# ATSAMA5D31 device description
Architecture: CORTEX-A5; Family: SAMA5
Registers are 32-bit, read-write, no defined reset value unless marked. A register's access mark holds for its fields unless they carry their own. Offsets are from the block's base; [hi:lo] are bit positions; {n}, {i} and the like mark numbered series; 'fields as' and 'values as' point back to an identical list.

## SCKC — Slow Clock Controller
Instances: SCKC 0xFFFFFE50
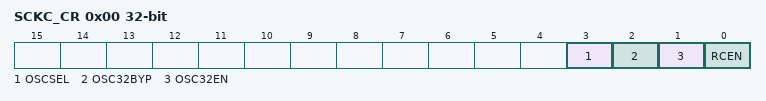
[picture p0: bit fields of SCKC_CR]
0x00 SCKC_CR — Slow Clock Configuration Register
  [3] OSCSEL — Slow Clock Selector
    0=RC (Slow clock is internal 32 kHz RC oscillator.); 1=XTAL (Slow clock is 32,768 Hz oscillator.)
  [2] OSC32BYP — 32,768Hz Oscillator Bypass
  [1] OSC32EN — 32,768 Hz Oscillator
  [0] RCEN — Internal 32 kHz RC Oscillator

## SFR — Special Function Registers
Instances: SFR 0xF0038000
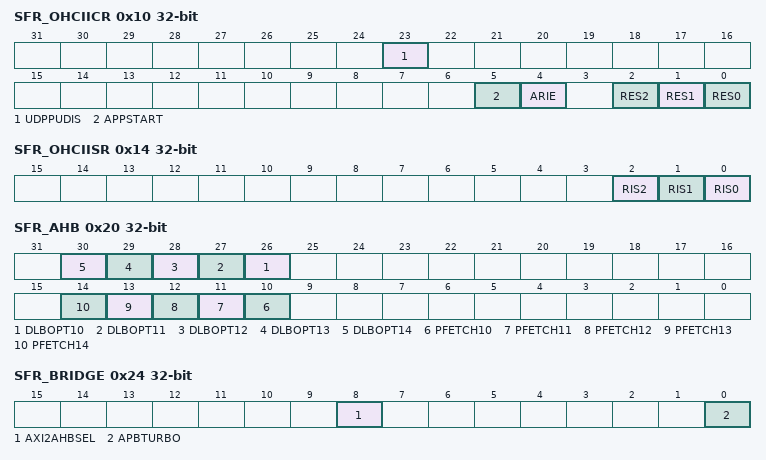
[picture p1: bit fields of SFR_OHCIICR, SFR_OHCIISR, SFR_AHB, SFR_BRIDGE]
0x10 SFR_OHCIICR — OHCI Interrupt Configuration Register
  [23] UDPPUDIS — OHCI USB DEVICE PULL-UP DISABLE
  [5] APPSTART — Reserved
  [4] ARIE — OHCI Asynchronous Resume Interrupt Enable
  [2] RES2 — USB PORTx RESET
  [1] RES1 — USB PORTx RESET
  [0] RES0 — USB PORTx RESET
0x14 SFR_OHCIISR ro — OHCI Interrupt Status Register
  [2] RIS2 — OHCI Resume Interrupt Status Port 2
  [1] RIS1 — OHCI Resume Interrupt Status Port 1
  [0] RIS0 — OHCI Resume Interrupt Status Port 0
0x20 SFR_AHB — AHB Configuration Register
  [n+16] DLBOPT{n} (n=10..14) — AHB MASTERx {n} Converter Define Length Burst Optimization
  [n] PFETCH{n} (n=10..14) — AHB MASTERx {n} Converter Prefetch
    0=INCR4 (INCR undefined burst converted to burst of 4 beats.); 1=INCR8 (INCR undefined burst converted to burst of 8 beats.)
0x24 SFR_BRIDGE — Bridge Configuration Register
  [8] AXI2AHBSEL — AXI to AHB bridge for DDR controller selection
    0=SINGLE (use single port bridge.); 1=DUAL (use dual port bridge.)
  [0] APBTURBO — AHB to APB Bridge mode
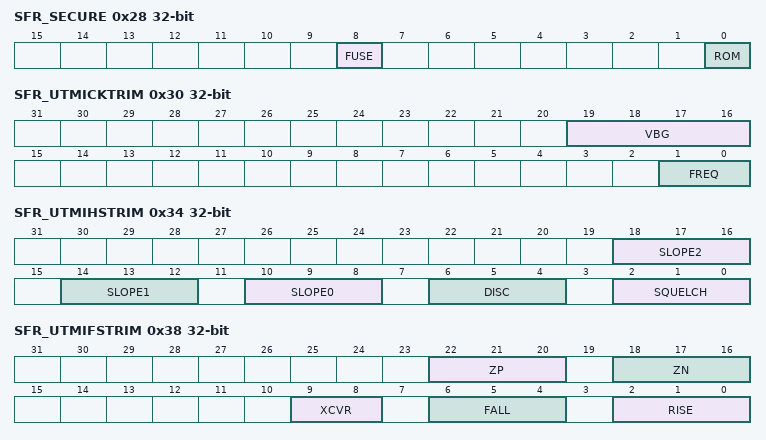
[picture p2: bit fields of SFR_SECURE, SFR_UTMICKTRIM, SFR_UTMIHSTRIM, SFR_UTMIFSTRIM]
0x28 SFR_SECURE — Security Configuration Register
  [8] FUSE — Disable Access to Fuse Controller
  [0] ROM — Disable Access to ROM Code
0x30 SFR_UTMICKTRIM — UTMI Clock Trimming Register
  [19:16] VBG — UTMI Band Gap Voltage Trimming
  [1:0] FREQ — UTMI Reference Clock Frequency
    0=12 MHz reference clock; 1=16 MHz reference clock; 2=24 MHz reference clock; 3=48 MHz reference clock
0x34 SFR_UTMIHSTRIM — UTMI High Speed Trimming Register
  [18:16] SLOPE2 — UTMI HS PORTx Transceiver Slope Trimming
  [14:12] SLOPE1 — UTMI HS PORTx Transceiver Slope Trimming
  [10:8] SLOPE0 — UTMI HS PORTx Transceiver Slope Trimming
  [6:4] DISC — UTMI Disconnect Voltage Trimming
  [2:0] SQUELCH — UTMI HS SQUELCH Voltage Trimming
0x38 SFR_UTMIFSTRIM — UTMI Full Speed Trimming Register
  [22:20] ZP — FS Transceiver PMOS impedance trimming
  [18:16] ZN — FS Transceiver NMOS impedance trimming
  [9:8] XCVR — FS Transceiver crossover voltage trimming
  [6:4] FALL — FS Transceiver output falling slope trimming
  [2:0] RISE — FS Transceiver output rising slope trimming
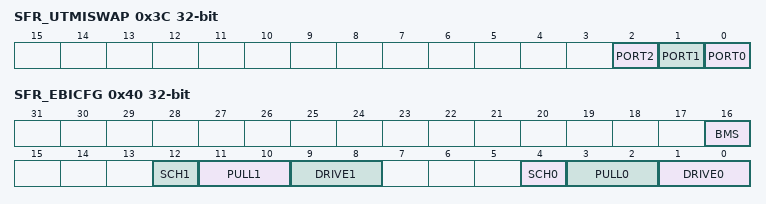
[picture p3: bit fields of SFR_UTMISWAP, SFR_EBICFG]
0x3C SFR_UTMISWAP — UTMI DP/DM Pin Swapping Register
  [all] fields
    0=NORMAL (DP/DM normal pinout.); 1=SWAPPED (DP/DM swapped pinout.)
  [2] PORT2 — PORT 2 DP/DM Pin Swapping
  [1] PORT1 — PORT 1 DP/DM Pin Swapping
  [0] PORT0 — PORT 0 DP/DM Pin Swapping
0x40 SFR_EBICFG — EBI Configuration Register
  [16] BMS — BMS Sampled Value (Read Only)
    0=ROM (Boot on ROM.); 1=EBI (Boot on EBI.)
  [12] SCH1 — EBI Pins Schmitt Trigger
  [11:10] PULL1 — EBI Pins Pull Value
    0=UP (Pull-up); 1=NONE (No Pull); 3=DOWN (Pull-down)
  [9:8] DRIVE1 — EBI Pins Drive Level
    0=LOW (Low drive level); 2=MEDIUM (Medium drive level); 3=HIGH (High drive level)
  [4] SCH0 — EBI Pins Schmitt Trigger
  [3:2] PULL0 — EBI Pins Pull Value
    0=UP (Pull-up); 1=NONE (No Pull); 3=DOWN (Pull-down)
  [1:0] DRIVE0 — EBI Pins Drive Level
    values as DRIVE1

## SHDWC — Shutdown Controller
Instances: SHDWC 0xFFFFFE10
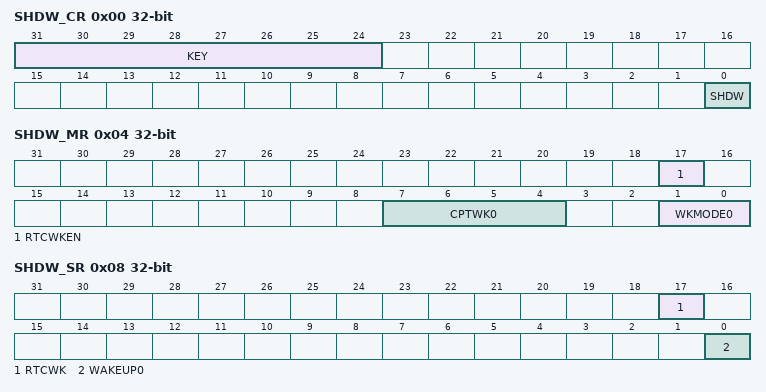
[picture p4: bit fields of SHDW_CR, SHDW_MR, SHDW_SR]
0x00 SHDW_CR wo — Shutdown Control Register
  [31:24] KEY — Password
  [0] SHDW — Shutdown Command
0x04 SHDW_MR — Shutdown Mode Register
  [17] RTCWKEN — Real-time Clock Wake-up Enable
  [7:4] CPTWK0 — Counter on Wake-up 0
  [1:0] WKMODE0 — Wake-up Mode 0
0x08 SHDW_SR ro — Shutdown Status Register
  [17] RTCWK — Real-time Clock Wake-up
  [0] WAKEUP0 — Wake-up 0 Status
